VERSION "1.0"

BU_: BROADCASTER RECEIVER1 RECEIVER2

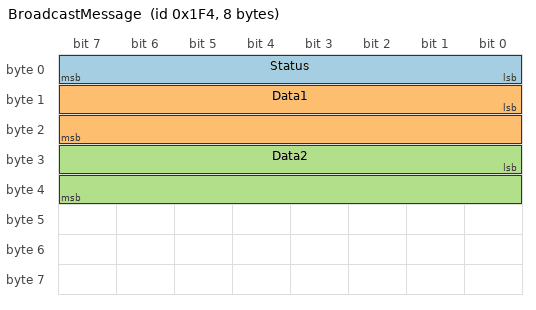
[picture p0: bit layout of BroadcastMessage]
BO_ 500 BroadcastMessage : 8 BROADCASTER
 SG_ Status : 0|8@1+ (1,0) [0|255] "" *
 SG_ Data1 : 8|16@1+ (0.1,0) [0|6553.5] "" RECEIVER1 RECEIVER2
 SG_ Data2 : 24|16@1+ (0.01,0) [0|655.35] "" RECEIVER1
